# LM4F230H5QR register map
File version: 7944
Registers are 32-bit, read-write, no defined reset value unless marked. A register's access mark holds for its fields unless they carry their own. Offsets are from the block's base; [hi:lo] are bit positions.

## I2C0 — Register map for I2C0 peripheral
Base 0x40020000; register names take the prefix I2C0
Same registers: I2C1 0x40021000 (register names take the prefix I2C1), I2C2 0x40022000 (register names take the prefix I2C2), I2C3 0x40023000 (register names take the prefix I2C3)
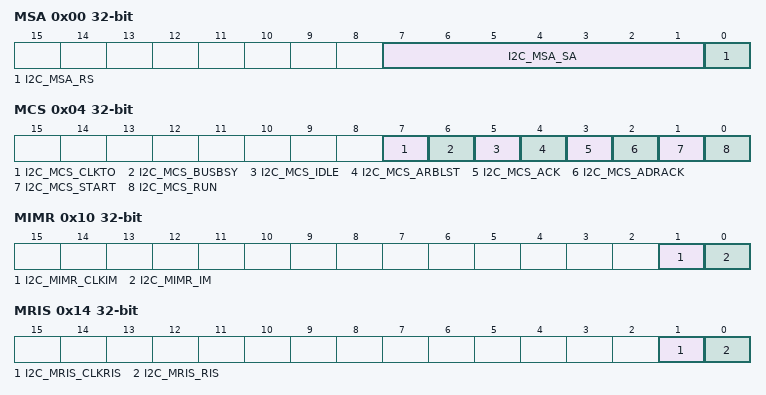
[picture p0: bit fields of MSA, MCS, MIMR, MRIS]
0x00 MSA — I2C Master Slave Address
  [7:1] I2C_MSA_SA — I2C Slave Address
  [0] I2C_MSA_RS — Receive not send
0x04 MCS — I2C Master Control/Status
  [7] I2C_MCS_CLKTO — Clock Timeout Error
  [6] I2C_MCS_BUSBSY — Bus Busy
  [5] I2C_MCS_IDLE — I2C Idle
  [4] I2C_MCS_ARBLST — Arbitration Lost
  [3] I2C_MCS_ACK — Data Acknowledge Enable
  [2] I2C_MCS_ADRACK — Acknowledge Address
  [1] I2C_MCS_START — Generate START
  [0] I2C_MCS_RUN — I2C Master Enable
0x04 MCS (I2C0_ALT view) — I2C Master Control/Status
  [3] I2C_MCS_DATACK — Acknowledge Data
  [2] I2C_MCS_STOP — Generate STOP
  [1] I2C_MCS_ERROR — Error
  [0] I2C_MCS_BUSY — I2C Busy
0x08 MDR — I2C Master Data
  [7:0] I2C_MDR_DATA — Data Transferred
0x0C MTPR — I2C Master Timer Period
  [6:0] I2C_MTPR_TPR — SCL Clock Period
0x10 MIMR — I2C Master Interrupt Mask
  [1] I2C_MIMR_CLKIM — Clock Timeout Interrupt Mask
  [0] I2C_MIMR_IM — Interrupt Mask
0x14 MRIS — I2C Master Raw Interrupt Status
  [1] I2C_MRIS_CLKRIS — Clock Timeout Raw Interrupt Status
  [0] I2C_MRIS_RIS — Raw Interrupt Status
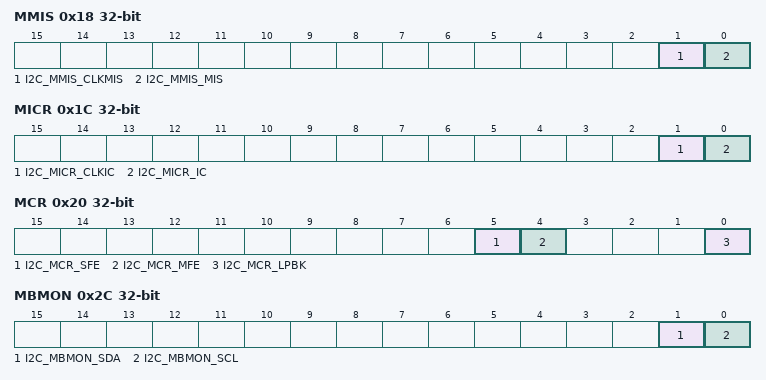
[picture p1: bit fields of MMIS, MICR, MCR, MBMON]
0x18 MMIS — I2C Master Masked Interrupt Status
  [1] I2C_MMIS_CLKMIS — Clock Timeout Masked Interrupt Status
  [0] I2C_MMIS_MIS — Masked Interrupt Status
0x1C MICR wo — I2C Master Interrupt Clear
  [1] I2C_MICR_CLKIC — Clock Timeout Interrupt Clear
  [0] I2C_MICR_IC — Interrupt Clear
0x20 MCR — I2C Master Configuration
  [5] I2C_MCR_SFE — I2C Slave Function Enable
  [4] I2C_MCR_MFE — I2C Master Function Enable
  [0] I2C_MCR_LPBK — I2C Loopback
0x24 MCLKOCNT — I2C Master Clock Low Timeout Count
  [7:0] I2C_MCLKOCNT_CNTL — I2C Master Count
0x2C MBMON — I2C Master Bus Monitor
  [1] I2C_MBMON_SDA — I2C SDA Status
  [0] I2C_MBMON_SCL — I2C SCL Status
0x800 SOAR — I2C Slave Own Address
  [6:0] I2C_SOAR_OAR
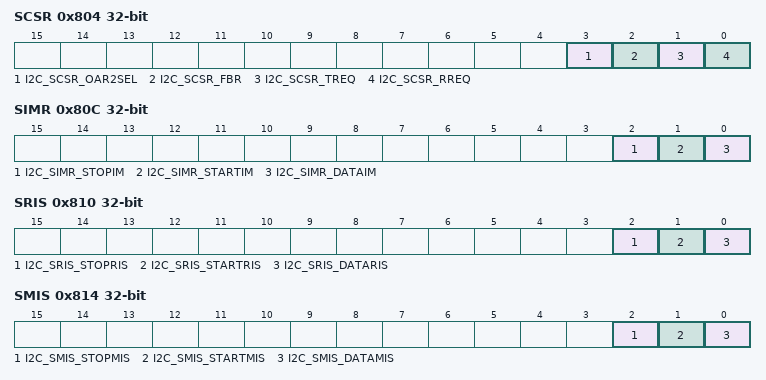
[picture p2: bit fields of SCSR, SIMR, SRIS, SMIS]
0x804 SCSR — I2C Slave Control/Status
  [3] I2C_SCSR_OAR2SEL — OAR2 Address Matched
  [2] I2C_SCSR_FBR — First Byte Received
  [1] I2C_SCSR_TREQ — Transmit Request
  [0] I2C_SCSR_RREQ — Receive Request
0x804 SCSR (I2C0_ALT view) — I2C Slave Control/Status
  [0] I2C_SCSR_DA — Device Active
0x808 SDR — I2C Slave Data
  [7:0] I2C_SDR_DATA — Data for Transfer
0x80C SIMR — I2C Slave Interrupt Mask
  [2] I2C_SIMR_STOPIM — Stop Condition Interrupt Mask
  [1] I2C_SIMR_STARTIM — Start Condition Interrupt Mask
  [0] I2C_SIMR_DATAIM — Data Interrupt Mask
0x810 SRIS — I2C Slave Raw Interrupt Status
  [2] I2C_SRIS_STOPRIS — Stop Condition Raw Interrupt Status
  [1] I2C_SRIS_STARTRIS — Start Condition Raw Interrupt Status
  [0] I2C_SRIS_DATARIS — Data Raw Interrupt Status
0x814 SMIS — I2C Slave Masked Interrupt Status
  [2] I2C_SMIS_STOPMIS — Stop Condition Masked Interrupt Status
  [1] I2C_SMIS_STARTMIS — Start Condition Masked Interrupt Status
  [0] I2C_SMIS_DATAMIS — Data Masked Interrupt Status
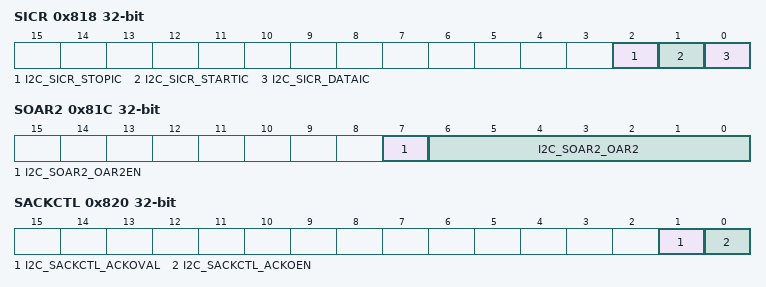
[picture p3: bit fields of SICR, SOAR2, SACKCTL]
0x818 SICR wo — I2C Slave Interrupt Clear
  [2] I2C_SICR_STOPIC — Stop Condition Interrupt Clear
  [1] I2C_SICR_STARTIC — Start Condition Interrupt Clear
  [0] I2C_SICR_DATAIC — Data Interrupt Clear
0x81C SOAR2 — I2C Slave Own Address 2
  [7] I2C_SOAR2_OAR2EN — I2C Slave Own Address 2 Enable
  [6:0] I2C_SOAR2_OAR2 — I2C Slave Own Address 2
0x820 SACKCTL — I2C ACK Control
  [1] I2C_SACKCTL_ACKOVAL — I2C Slave ACK Override Value
  [0] I2C_SACKCTL_ACKOEN — I2C Slave ACK Override Enable
0xFC0 PP — I2C Peripheral Properties
  [0] I2C_PP_HS — High-Speed Capable

## QEI0 — Register map for QEI0 peripheral
Base 0x4002C000; register names take the prefix QEI0
Same registers: QEI1 0x4002D000 (register names take the prefix QEI1)
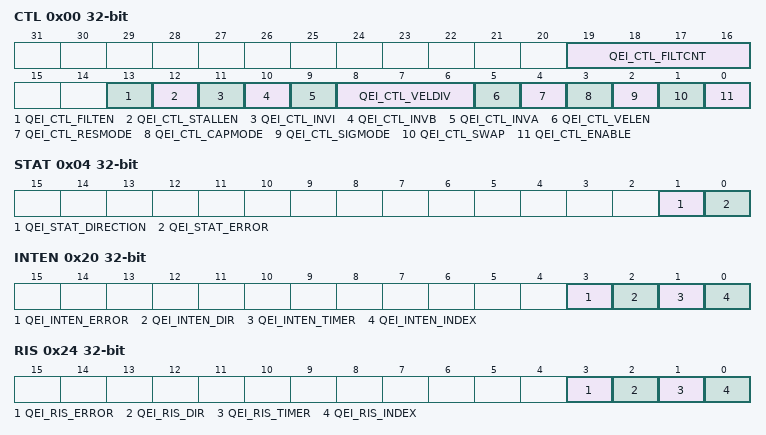
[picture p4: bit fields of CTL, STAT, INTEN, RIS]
0x00 CTL — QEI Control
  [19:16] QEI_CTL_FILTCNT — Input Filter Prescale Count
  [13] QEI_CTL_FILTEN — Enable Input Filter
  [12] QEI_CTL_STALLEN — Stall QEI
  [11] QEI_CTL_INVI — Invert Index Pulse
  [10] QEI_CTL_INVB — Invert PhB
  [9] QEI_CTL_INVA — Invert PhA
  [8:6] QEI_CTL_VELDIV — Predivide Velocity
    0=QEI clock /1; 1=QEI clock /2; 2=QEI clock /4; 3=QEI clock /8; 4=QEI clock /16; 5=QEI clock /32; 6=QEI clock /64; 7=QEI clock /128
  [5] QEI_CTL_VELEN — Capture Velocity
  [4] QEI_CTL_RESMODE — Reset Mode
  [3] QEI_CTL_CAPMODE — Capture Mode
  [2] QEI_CTL_SIGMODE — Signal Mode
  [1] QEI_CTL_SWAP — Swap Signals
  [0] QEI_CTL_ENABLE — Enable QEI
0x04 STAT — QEI Status
  [1] QEI_STAT_DIRECTION — Direction of Rotation
  [0] QEI_STAT_ERROR — Error Detected
0x08 POS — QEI Position
  [31:0] QEI_POS — Current Position Integrator Value
0x0C MAXPOS — QEI Maximum Position
  [31:0] QEI_MAXPOS — Maximum Position Integrator Value
0x10 LOAD — QEI Timer Load
  [31:0] QEI_LOAD — Velocity Timer Load Value
0x14 TIME — QEI Timer
  [31:0] QEI_TIME — Velocity Timer Current Value
0x18 COUNT — QEI Velocity Counter
  [31:0] QEI_COUNT — Velocity Pulse Count
0x1C SPEED — QEI Velocity
  [31:0] QEI_SPEED — Velocity
0x20 INTEN — QEI Interrupt Enable
  [3] QEI_INTEN_ERROR — Phase Error Interrupt Enable
  [2] QEI_INTEN_DIR — Direction Change Interrupt Enable
  [1] QEI_INTEN_TIMER — Timer Expires Interrupt Enable
  [0] QEI_INTEN_INDEX — Index Pulse Detected Interrupt Enable
0x24 RIS — QEI Raw Interrupt Status
  [3] QEI_RIS_ERROR — Phase Error Detected
  [2] QEI_RIS_DIR — Direction Change Detected
  [1] QEI_RIS_TIMER — Velocity Timer Expired
  [0] QEI_RIS_INDEX — Index Pulse Asserted
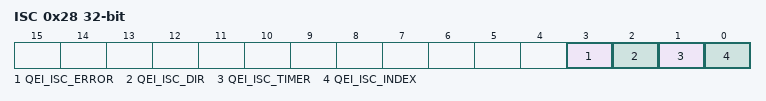
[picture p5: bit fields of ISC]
0x28 ISC — QEI Interrupt Status and Clear
  [3] QEI_ISC_ERROR — Phase Error Interrupt
  [2] QEI_ISC_DIR — Direction Change Interrupt
  [1] QEI_ISC_TIMER — Velocity Timer Expired Interrupt
  [0] QEI_ISC_INDEX — Index Pulse Interrupt
